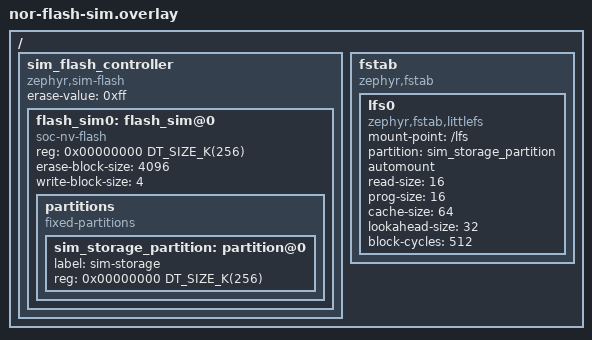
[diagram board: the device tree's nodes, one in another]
/ {
	sim_flash_controller: sim_flash_controller {
		compatible = "zephyr,sim-flash";

		#address-cells = <1>;
		#size-cells = <1>;
		erase-value = <0xff>;

		flash_sim0: flash_sim@0 {
			compatible = "soc-nv-flash";
			reg = <0x00000000 DT_SIZE_K(256)>;

			erase-block-size = <4096>;
			write-block-size = <4>;

			partitions {
				compatible = "fixed-partitions";
				#address-cells = <1>;
				#size-cells = <1>;

				sim_storage_partition: partition@0 {
					label = "sim-storage";
					reg = <0x00000000 DT_SIZE_K(256)>;
				};
			};
		};
	};

	fstab {
		compatible = "zephyr,fstab";
		lfs0: lfs0 {
			compatible = "zephyr,fstab,littlefs";
			mount-point = "/lfs";
			partition = <&sim_storage_partition>;
			automount;
			read-size = <16>;
			prog-size = <16>;
			cache-size = <64>;
			lookahead-size = <32>;
			block-cycles = <512>;
		};
	};
};
